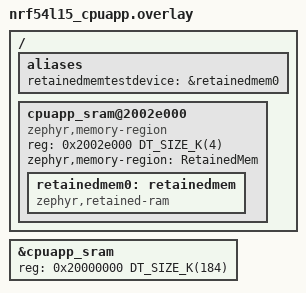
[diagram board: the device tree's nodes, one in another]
/ {
	aliases {
		retainedmemtestdevice = &retainedmem0;
	};

	cpuapp_sram@2002e000 {
		compatible = "zephyr,memory-region", "mmio-sram";
		reg = <0x2002e000 DT_SIZE_K(4)>;
		ranges = <0x0 0x2002e000 DT_SIZE_K(4)>;
		#address-cells = <1>;
		#size-cells = <1>;
		zephyr,memory-region = "RetainedMem";
		status = "okay";

		retainedmem0: retainedmem {
			compatible = "zephyr,retained-ram";
			ranges;
			#address-cells = <1>;
			#size-cells = <1>;
			status = "okay";
		};
	};
};

&cpuapp_sram {
	reg = <0x20000000 DT_SIZE_K(184)>;
	ranges = <0x0 0x20000000 0x2e000>;
};
